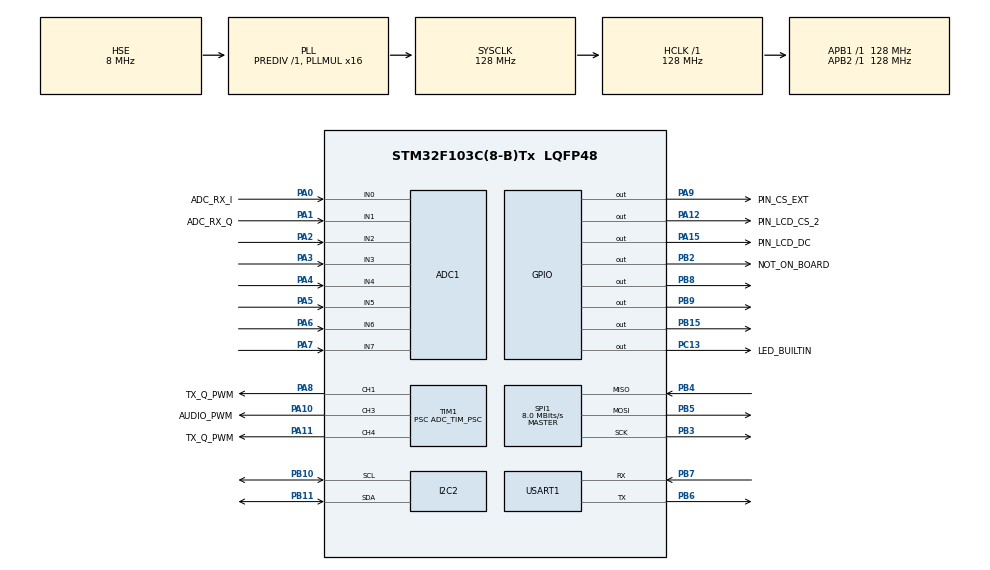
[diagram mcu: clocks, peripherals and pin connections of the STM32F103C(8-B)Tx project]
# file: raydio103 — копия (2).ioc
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ADC1.Channel-14\#ChannelRegularConversion=ADC_CHANNEL_1
ADC1.Channel-15\#ChannelInjectedConversion=ADC_CHANNEL_4
ADC1.Channel-16\#ChannelInjectedConversion=ADC_CHANNEL_5
ADC1.Channel-17\#ChannelRegularConversion=ADC_CHANNEL_2
ADC1.Channel-18\#ChannelRegularConversion=ADC_CHANNEL_3
ADC1.Channel-9\#ChannelRegularConversion=ADC_CHANNEL_0
ADC1.ContinuousConvMode=DISABLE
ADC1.DiscontinuousConvMode=DISABLE
ADC1.EnableInjectedConversion=ENABLE
ADC1.EnableRegularConversion=ENABLE
ADC1.ExternalTrigConv=ADC_EXTERNALTRIGCONV_T1_CC2
ADC1.InjNumberOfConversion=2
ADC1.InjectedConvMode=AutoInjected
ADC1.InjectedOffset-15\#ChannelInjectedConversion=0
ADC1.InjectedOffset-16\#ChannelInjectedConversion=0
ADC1.InjectedRank-15\#ChannelInjectedConversion=1
ADC1.InjectedRank-16\#ChannelInjectedConversion=2
ADC1.NbrOfConversion=4
ADC1.NbrOfConversionFlag=1
ADC1.Rank-14\#ChannelRegularConversion=2
ADC1.Rank-17\#ChannelRegularConversion=3
ADC1.Rank-18\#ChannelRegularConversion=4
ADC1.Rank-9\#ChannelRegularConversion=1
ADC1.SamplingTime-14\#ChannelRegularConversion=ADC_SAMPLETIME_71CYCLES_5
ADC1.SamplingTime-15\#ChannelInjectedConversion=ADC_SAMPLETIME_28CYCLES_5
ADC1.SamplingTime-16\#ChannelInjectedConversion=ADC_SAMPLETIME_28CYCLES_5
ADC1.SamplingTime-17\#ChannelRegularConversion=ADC_SAMPLETIME_71CYCLES_5
ADC1.SamplingTime-18\#ChannelRegularConversion=ADC_SAMPLETIME_71CYCLES_5
ADC1.SamplingTime-9\#ChannelRegularConversion=ADC_SAMPLETIME_71CYCLES_5
ADC1.master=1
Dma.ADC1.0.Direction=DMA_PERIPH_TO_MEMORY
Dma.ADC1.0.Instance=DMA1_Channel1
Dma.ADC1.0.MemDataAlignment=DMA_MDATAALIGN_HALFWORD
Dma.ADC1.0.MemInc=DMA_MINC_ENABLE
Dma.ADC1.0.Mode=DMA_CIRCULAR
Dma.ADC1.0.PeriphDataAlignment=DMA_PDATAALIGN_HALFWORD
Dma.ADC1.0.PeriphInc=DMA_PINC_DISABLE
Dma.ADC1.0.Priority=DMA_PRIORITY_VERY_HIGH
Dma.Request0=ADC1
Dma.Request1=TIM1_CH3
Dma.Request2=TIM1_CH4/TRIG/COM
Dma.Request3=TIM1_CH1
Dma.Request4=SPI1_TX
Dma.SPI1_TX.4.Direction=DMA_MEMORY_TO_PERIPH
Dma.SPI1_TX.4.Instance=DMA1_Channel3
Dma.SPI1_TX.4.MemDataAlignment=DMA_MDATAALIGN_BYTE
Dma.SPI1_TX.4.MemInc=DMA_MINC_ENABLE
Dma.SPI1_TX.4.Mode=DMA_NORMAL
Dma.SPI1_TX.4.PeriphDataAlignment=DMA_PDATAALIGN_BYTE
Dma.SPI1_TX.4.PeriphInc=DMA_PINC_DISABLE
Dma.SPI1_TX.4.Priority=DMA_PRIORITY_MEDIUM
Dma.TIM1_CH1.3.Direction=DMA_MEMORY_TO_PERIPH
Dma.TIM1_CH1.3.Instance=DMA1_Channel2
Dma.TIM1_CH1.3.MemDataAlignment=DMA_MDATAALIGN_HALFWORD
Dma.TIM1_CH1.3.MemInc=DMA_MINC_ENABLE
Dma.TIM1_CH1.3.Mode=DMA_NORMAL
Dma.TIM1_CH1.3.PeriphDataAlignment=DMA_PDATAALIGN_HALFWORD
Dma.TIM1_CH1.3.PeriphInc=DMA_PINC_DISABLE
Dma.TIM1_CH1.3.Priority=DMA_PRIORITY_LOW
Dma.TIM1_CH3.1.Direction=DMA_MEMORY_TO_PERIPH
Dma.TIM1_CH3.1.Instance=DMA1_Channel6
Dma.TIM1_CH3.1.MemDataAlignment=DMA_MDATAALIGN_HALFWORD
Dma.TIM1_CH3.1.MemInc=DMA_MINC_ENABLE
Dma.TIM1_CH3.1.Mode=DMA_CIRCULAR
Dma.TIM1_CH3.1.PeriphDataAlignment=DMA_PDATAALIGN_HALFWORD
Dma.TIM1_CH3.1.PeriphInc=DMA_PINC_DISABLE
Dma.TIM1_CH3.1.Priority=DMA_PRIORITY_HIGH
Dma.TIM1_CH4/TRIG/COM.2.Direction=DMA_MEMORY_TO_PERIPH
Dma.TIM1_CH4/TRIG/COM.2.Instance=DMA1_Channel4
Dma.TIM1_CH4/TRIG/COM.2.MemDataAlignment=DMA_MDATAALIGN_HALFWORD
Dma.TIM1_CH4/TRIG/COM.2.MemInc=DMA_MINC_ENABLE
Dma.TIM1_CH4/TRIG/COM.2.Mode=DMA_NORMAL
Dma.TIM1_CH4/TRIG/COM.2.PeriphDataAlignment=DMA_PDATAALIGN_HALFWORD
Dma.TIM1_CH4/TRIG/COM.2.PeriphInc=DMA_PINC_DISABLE
Dma.TIM1_CH4/TRIG/COM.2.Priority=DMA_PRIORITY_LOW
Mcu.Family=STM32F1
Mcu.Name=STM32F103C(8-B)Tx
Mcu.Package=LQFP48
Mcu.UserConstants=ADC_TIM_PSC,(2-1);ADC_TIM_PERIOD,(2048-1)
NVIC.DMA1_Channel1_IRQn=true\:0\:0\:false\:false\:true\:false\:true\:true
NVIC.DMA1_Channel2_IRQn=true\:0\:0\:false\:false\:true\:false\:true\:true
NVIC.DMA1_Channel3_IRQn=true\:0\:0\:false\:false\:true\:false\:true\:true
NVIC.DMA1_Channel4_IRQn=true\:0\:0\:false\:false\:true\:false\:true\:true
NVIC.DMA1_Channel6_IRQn=true\:0\:0\:false\:false\:true\:false\:true\:true
NVIC.PriorityGroup=NVIC_PRIORITYGROUP_4
NVIC.USART1_IRQn=true\:0\:0\:false\:false\:true\:true\:true\:true
PA0-WKUP.GPIO_Label=ADC_RX_I
PA0-WKUP.Signal=ADCx_IN0
PA1.GPIO_Label=ADC_RX_Q
PA1.Signal=ADCx_IN1
PA10.GPIO_Label=AUDIO_PWM
PA10.Signal=S_TIM1_CH3
PA11.GPIO_Label=TX_Q_PWM
PA11.Signal=S_TIM1_CH4
PA12.GPIO_Label=PIN_LCD_CS_2
PA12.GPIO_PuPd=GPIO_PULLUP
PA12.GPIO_Speed=GPIO_SPEED_FREQ_HIGH
PA12.PinState=GPIO_PIN_RESET
PA12.Signal=GPIO_Output
PA13.Mode=Serial_Wire
PA13.Signal=SYS_JTMS-SWDIO
PA14.Mode=Serial_Wire
PA14.Signal=SYS_JTCK-SWCLK
PA15.GPIO_Label=PIN_LCD_DC
PA15.GPIO_PuPd=GPIO_PULLDOWN
PA15.GPIO_Speed=GPIO_SPEED_FREQ_HIGH
PA15.Signal=GPIO_Output
PA2.Signal=ADCx_IN2
PA3.Signal=ADCx_IN3
PA4.Signal=ADCx_IN4
PA5.Signal=ADCx_IN5
PA6.Signal=ADCx_IN6
PA7.Signal=ADCx_IN7
PA8.GPIO_Label=TX_Q_PWM
PA8.Signal=S_TIM1_CH1
PA9.GPIO_Label=PIN_CS_EXT
PA9.Signal=GPIO_Output
PB10.Mode=I2C
PB10.Signal=I2C2_SCL
PB11.Mode=I2C
PB11.Signal=I2C2_SDA
PB15.Signal=GPIO_Output
PB2.GPIO_Label=NOT_ON_BOARD
PB2.Signal=GPIO_Output
PB3.Mode=Full_Duplex_Master
PB3.Signal=SPI1_SCK
PB4.Mode=Full_Duplex_Master
PB4.Signal=SPI1_MISO
PB5.Mode=Full_Duplex_Master
PB5.Signal=SPI1_MOSI
PB6.Mode=Asynchronous
PB6.Signal=USART1_TX
PB7.Mode=Asynchronous
PB7.Signal=USART1_RX
PB8.Signal=GPIO_Output
PB9.Signal=GPIO_Output
PC13-TAMPER-RTC.GPIO_Label=LED_BUILTIN
PC13-TAMPER-RTC.Signal=GPIO_Output
PC14-OSC32_IN.Mode=LSE-External-Oscillator
PC14-OSC32_IN.Signal=RCC_OSC32_IN
PC15-OSC32_OUT.Mode=LSE-External-Oscillator
PC15-OSC32_OUT.Signal=RCC_OSC32_OUT
PD0-OSC_IN.Mode=HSE-External-Oscillator
PD0-OSC_IN.Signal=RCC_OSC_IN
PD1-OSC_OUT.Mode=HSE-External-Oscillator
PD1-OSC_OUT.Signal=RCC_OSC_OUT
ProjectManager.HeapSize=0x400
ProjectManager.StackSize=0x200
ProjectManager.TargetToolchain=STM32CubeIDE
RCC.ADCPresc=RCC_ADCPCLK2_DIV4
RCC.AHBFreq_Value=128000000
RCC.APB1Freq_Value=128000000
RCC.APB1TimFreq_Value=128000000
RCC.APB2Freq_Value=128000000
RCC.APB2TimFreq_Value=128000000
RCC.HCLKFreq_Value=128000000
RCC.PLLMUL=RCC_PLL_MUL16
RCC.PLLSourceVirtual=RCC_PLLSOURCE_HSE
RCC.SYSCLKFreq_VALUE=128000000
RCC.SYSCLKSource=RCC_SYSCLKSOURCE_PLLCLK
RCC.USBFreq_Value=85333333.33333333
RCC.USBPrescaler=RCC_USBCLKSOURCE_PLL_DIV1_5
RTC.Format=RTC_FORMAT_BIN
SH.ADCx_IN0.0=ADC1_IN0,IN0
SH.ADCx_IN1.0=ADC1_IN1,IN1
SH.ADCx_IN2.0=ADC1_IN2,IN2
SH.ADCx_IN3.0=ADC1_IN3,IN3
SH.ADCx_IN4.0=ADC1_IN4,IN4
SH.ADCx_IN5.0=ADC1_IN5,IN5
SH.ADCx_IN6.0=ADC1_IN6,IN6
SH.ADCx_IN7.0=ADC1_IN7,IN7
SH.S_TIM1_CH1.0=TIM1_CH1,PWM Generation1 CH1
SH.S_TIM1_CH3.0=TIM1_CH3,PWM Generation3 CH3
SH.S_TIM1_CH4.0=TIM1_CH4,PWM Generation4 CH4
SPI1.BaudRatePrescaler=SPI_BAUDRATEPRESCALER_16
SPI1.CLKPhase=SPI_PHASE_1EDGE
SPI1.CLKPolarity=SPI_POLARITY_LOW
SPI1.CalculateBaudRate=8.0 MBits/s
SPI1.Direction=SPI_DIRECTION_2LINES
SPI1.Mode=SPI_MODE_MASTER
SPI1.VirtualType=VM_MASTER
TIM1.AutoReloadPreload=TIM_AUTORELOAD_PRELOAD_ENABLE
TIM1.Channel-PWM\ Generation1\ CH1=TIM_CHANNEL_1
TIM1.Channel-PWM\ Generation2\ No\ Output=TIM_CHANNEL_2
TIM1.Channel-PWM\ Generation3\ CH3=TIM_CHANNEL_3
TIM1.Channel-PWM\ Generation4\ CH4=TIM_CHANNEL_4
TIM1.ClockDivision=TIM_CLOCKDIVISION_DIV1
TIM1.Period=ADC_TIM_PERIOD
TIM1.Prescaler=ADC_TIM_PSC
TIM1.Pulse-PWM\ Generation2\ No\ Output=1
TIM1.Pulse-PWM\ Generation3\ CH3=0
TIM1.TIM_MasterOutputTrigger=TIM_TRGO_ENABLE
TIM1.TIM_MasterSlaveMode=TIM_MASTERSLAVEMODE_DISABLE
TIM2.Channel-PWM\ Generation2\ No\ Output=TIM_CHANNEL_2
TIM2.Period=ADC_TIM_PERIOD
TIM2.Prescaler=ADC_TIM_PSC
TIM2.Pulse-PWM\ Generation2\ No\ Output=1
TIM2.TIM_MasterOutputTrigger=TIM_TRGO_ENABLE
TIM2.TIM_MasterSlaveMode=TIM_MASTERSLAVEMODE_ENABLE
USART1.VirtualMode=VM_ASYNC
VP_CRC_VS_CRC.Mode=CRC_Activate
VP_RTC_VS_RTC_Activate.Mode=RTC_Enabled
VP_TIM1_VS_ClockSourceINT.Mode=Internal
VP_TIM1_VS_no_output2.Mode=PWM Generation2 No Output
VP_TIM2_VS_ClockSourceINT.Mode=Internal
VP_TIM2_VS_ClockSourceITR.Mode=TriggerSource_ITR0
VP_TIM2_VS_ControllerModeTrigger.Mode=Trigger Mode
VP_TIM2_VS_no_output2.Mode=PWM Generation2 No Output
board=custom

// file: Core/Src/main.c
/* USER CODE BEGIN Header */
/**
  ******************************************************************************
  * @file           : main.c
  * @brief          : Main program body
  ******************************************************************************
  * @attention
  *
  * Copyright (c) 2022 STMicroelectronics.
  * All rights reserved.
  *
  * This software is licensed under terms that can be found in the LICENSE file
  * in the root directory of this software component.
  * If no LICENSE file comes with this software, it is provided AS-IS.
  *
  ******************************************************************************
  */
/* USER CODE END Header */
#include "main.h"

 ADC_HandleTypeDef hadc1;
DMA_HandleTypeDef hdma_adc1;

CRC_HandleTypeDef hcrc;

I2C_HandleTypeDef hi2c2;

RTC_HandleTypeDef hrtc;

SPI_HandleTypeDef hspi1;
DMA_HandleTypeDef hdma_spi1_tx;

TIM_HandleTypeDef htim1;
TIM_HandleTypeDef htim2;
DMA_HandleTypeDef hdma_tim1_ch3;
DMA_HandleTypeDef hdma_tim1_ch4_trig_com;
DMA_HandleTypeDef hdma_tim1_ch1;

UART_HandleTypeDef huart1;

void SystemClock_Config(void);
static void MX_GPIO_Init(void);
static void MX_DMA_Init(void);
static void MX_ADC1_Init(void);
static void MX_TIM1_Init(void);
static void MX_SPI1_Init(void);
static void MX_USART1_UART_Init(void);
static void MX_TIM2_Init(void);
static void MX_I2C2_Init(void);
static void MX_RTC_Init(void);
static void MX_CRC_Init(void);

int main(void)
{

  /* MCU Configuration--------------------------------------------------------*/

  /* Reset of all peripherals, Initializes the Flash interface and the Systick. */
  HAL_Init();

  /* Configure the system clock */
  SystemClock_Config();

  /* Initialize all configured peripherals */
  MX_GPIO_Init();
  MX_DMA_Init();
  MX_ADC1_Init();
  MX_TIM1_Init();
  MX_SPI1_Init();
  MX_USART1_UART_Init();
  MX_TIM2_Init();
  MX_I2C2_Init();
  MX_RTC_Init();
  MX_CRC_Init();

  /* Infinite loop */
  /* USER CODE BEGIN WHILE */

  schedRun();

  while (1)
  {
    /* USER CODE END WHILE */

  }
}

void SystemClock_Config(void)
{
  RCC_OscInitTypeDef RCC_OscInitStruct = {0};
  RCC_ClkInitTypeDef RCC_ClkInitStruct = {0};
  RCC_PeriphCLKInitTypeDef PeriphClkInit = {0};

  /** Initializes the RCC Oscillators according to the specified parameters
  * in the RCC_OscInitTypeDef structure.
  */
  RCC_OscInitStruct.OscillatorType = RCC_OSCILLATORTYPE_LSI|RCC_OSCILLATORTYPE_HSE;
  RCC_OscInitStruct.HSEState = RCC_HSE_ON;
  RCC_OscInitStruct.HSEPredivValue = RCC_HSE_PREDIV_DIV1;
  RCC_OscInitStruct.HSIState = RCC_HSI_ON;
  RCC_OscInitStruct.LSIState = RCC_LSI_ON;
  RCC_OscInitStruct.PLL.PLLState = RCC_PLL_ON;
  RCC_OscInitStruct.PLL.PLLSource = RCC_PLLSOURCE_HSE;
  RCC_OscInitStruct.PLL.PLLMUL = RCC_PLL_MUL16;
  if (HAL_RCC_OscConfig(&RCC_OscInitStruct) != HAL_OK)
  {
    Error_Handler();
  }

  /** Initializes the CPU, AHB and APB buses clocks
  */
  RCC_ClkInitStruct.ClockType = RCC_CLOCKTYPE_HCLK|RCC_CLOCKTYPE_SYSCLK
                              |RCC_CLOCKTYPE_PCLK1|RCC_CLOCKTYPE_PCLK2;
  RCC_ClkInitStruct.SYSCLKSource = RCC_SYSCLKSOURCE_PLLCLK;
  RCC_ClkInitStruct.AHBCLKDivider = RCC_SYSCLK_DIV1;
  RCC_ClkInitStruct.APB1CLKDivider = RCC_HCLK_DIV1;
  RCC_ClkInitStruct.APB2CLKDivider = RCC_HCLK_DIV1;

  if (HAL_RCC_ClockConfig(&RCC_ClkInitStruct, FLASH_LATENCY_2) != HAL_OK)
  {
    Error_Handler();
  }
  PeriphClkInit.PeriphClockSelection = RCC_PERIPHCLK_RTC|RCC_PERIPHCLK_ADC;
  PeriphClkInit.RTCClockSelection = RCC_RTCCLKSOURCE_LSI;
  PeriphClkInit.AdcClockSelection = RCC_ADCPCLK2_DIV4;
  if (HAL_RCCEx_PeriphCLKConfig(&PeriphClkInit) != HAL_OK)
  {
    Error_Handler();
  }
}

static void MX_ADC1_Init(void)
{

  ADC_ChannelConfTypeDef sConfig = {0};
  ADC_InjectionConfTypeDef sConfigInjected = {0};

  /** Common config
  */
  hadc1.Instance = ADC1;
  hadc1.Init.ScanConvMode = ADC_SCAN_ENABLE;
  hadc1.Init.ContinuousConvMode = DISABLE;
  hadc1.Init.DiscontinuousConvMode = DISABLE;
  hadc1.Init.ExternalTrigConv = ADC_EXTERNALTRIGCONV_T1_CC2;
  hadc1.Init.DataAlign = ADC_DATAALIGN_RIGHT;
  hadc1.Init.NbrOfConversion = 4;
  if (HAL_ADC_Init(&hadc1) != HAL_OK)
  {
    Error_Handler();
  }

  /** Configure Regular Channel
  */
  sConfig.Channel = ADC_CHANNEL_0;
  sConfig.Rank = ADC_REGULAR_RANK_1;
  sConfig.SamplingTime = ADC_SAMPLETIME_71CYCLES_5;
  if (HAL_ADC_ConfigChannel(&hadc1, &sConfig) != HAL_OK)
  {
    Error_Handler();
  }

  /** Configure Regular Channel
  */
  sConfig.Channel = ADC_CHANNEL_1;
  sConfig.Rank = ADC_REGULAR_RANK_2;
  if (HAL_ADC_ConfigChannel(&hadc1, &sConfig) != HAL_OK)
  {
    Error_Handler();
  }

  /** Configure Regular Channel
  */
  sConfig.Channel = ADC_CHANNEL_2;
  sConfig.Rank = ADC_REGULAR_RANK_3;
  if (HAL_ADC_ConfigChannel(&hadc1, &sConfig) != HAL_OK)
  {
    Error_Handler();
  }

  /** Configure Regular Channel
  */
  sConfig.Channel = ADC_CHANNEL_3;
  sConfig.Rank = ADC_REGULAR_RANK_4;
  if (HAL_ADC_ConfigChannel(&hadc1, &sConfig) != HAL_OK)
  {
    Error_Handler();
  }

  /** Configure Injected Channel
  */
  sConfigInjected.InjectedChannel = ADC_CHANNEL_4;
  sConfigInjected.InjectedRank = ADC_INJECTED_RANK_1;
  sConfigInjected.InjectedNbrOfConversion = 2;
  sConfigInjected.InjectedSamplingTime = ADC_SAMPLETIME_28CYCLES_5;
  sConfigInjected.ExternalTrigInjecConv = ADC_INJECTED_SOFTWARE_START;
  sConfigInjected.AutoInjectedConv = ENABLE;
  sConfigInjected.InjectedDiscontinuousConvMode = DISABLE;
  sConfigInjected.InjectedOffset = 0;
  if (HAL_ADCEx_InjectedConfigChannel(&hadc1, &sConfigInjected) != HAL_OK)
  {
    Error_Handler();
  }

  /** Configure Injected Channel
  */
  sConfigInjected.InjectedChannel = ADC_CHANNEL_5;
  sConfigInjected.InjectedRank = ADC_INJECTED_RANK_2;
  if (HAL_ADCEx_InjectedConfigChannel(&hadc1, &sConfigInjected) != HAL_OK)
  {
    Error_Handler();
  }

}

static void MX_CRC_Init(void)
{

  hcrc.Instance = CRC;
  if (HAL_CRC_Init(&hcrc) != HAL_OK)
  {
    Error_Handler();
  }

}

static void MX_I2C2_Init(void)
{

  hi2c2.Instance = I2C2;
  hi2c2.Init.ClockSpeed = 100000;
  hi2c2.Init.DutyCycle = I2C_DUTYCYCLE_2;
  hi2c2.Init.OwnAddress1 = 0;
  hi2c2.Init.AddressingMode = I2C_ADDRESSINGMODE_7BIT;
  hi2c2.Init.DualAddressMode = I2C_DUALADDRESS_DISABLE;
  hi2c2.Init.OwnAddress2 = 0;
  hi2c2.Init.GeneralCallMode = I2C_GENERALCALL_DISABLE;
  hi2c2.Init.NoStretchMode = I2C_NOSTRETCH_DISABLE;
  if (HAL_I2C_Init(&hi2c2) != HAL_OK)
  {
    Error_Handler();
  }

}

static void MX_RTC_Init(void)
{

  /** Initialize RTC Only
  */
  hrtc.Instance = RTC;
  hrtc.Init.AsynchPrediv = RTC_AUTO_1_SECOND;
  hrtc.Init.OutPut = RTC_OUTPUTSOURCE_ALARM;
  if (HAL_RTC_Init(&hrtc) != HAL_OK)
  {
    Error_Handler();
  }

}

static void MX_SPI1_Init(void)
{

  /* SPI1 parameter configuration*/
  hspi1.Instance = SPI1;
  hspi1.Init.Mode = SPI_MODE_MASTER;
  hspi1.Init.Direction = SPI_DIRECTION_2LINES;
  hspi1.Init.DataSize = SPI_DATASIZE_8BIT;
  hspi1.Init.CLKPolarity = SPI_POLARITY_LOW;
  hspi1.Init.CLKPhase = SPI_PHASE_1EDGE;
  hspi1.Init.NSS = SPI_NSS_SOFT;
  hspi1.Init.BaudRatePrescaler = SPI_BAUDRATEPRESCALER_16;
  hspi1.Init.FirstBit = SPI_FIRSTBIT_MSB;
  hspi1.Init.TIMode = SPI_TIMODE_DISABLE;
  hspi1.Init.CRCCalculation = SPI_CRCCALCULATION_DISABLE;
  hspi1.Init.CRCPolynomial = 10;
  if (HAL_SPI_Init(&hspi1) != HAL_OK)
  {
    Error_Handler();
  }

}

static void MX_TIM1_Init(void)
{

  TIM_ClockConfigTypeDef sClockSourceConfig = {0};
  TIM_MasterConfigTypeDef sMasterConfig = {0};
  TIM_OC_InitTypeDef sConfigOC = {0};
  TIM_BreakDeadTimeConfigTypeDef sBreakDeadTimeConfig = {0};

  htim1.Instance = TIM1;
  htim1.Init.Prescaler = ADC_TIM_PSC;
  htim1.Init.CounterMode = TIM_COUNTERMODE_UP;
  htim1.Init.Period = ADC_TIM_PERIOD;
  htim1.Init.ClockDivision = TIM_CLOCKDIVISION_DIV1;
  htim1.Init.RepetitionCounter = 0;
  htim1.Init.AutoReloadPreload = TIM_AUTORELOAD_PRELOAD_ENABLE;
  if (HAL_TIM_Base_Init(&htim1) != HAL_OK)
  {
    Error_Handler();
  }
  sClockSourceConfig.ClockSource = TIM_CLOCKSOURCE_INTERNAL;
  if (HAL_TIM_ConfigClockSource(&htim1, &sClockSourceConfig) != HAL_OK)
  {
    Error_Handler();
  }
  if (HAL_TIM_PWM_Init(&htim1) != HAL_OK)
  {
    Error_Handler();
  }
  sMasterConfig.MasterOutputTrigger = TIM_TRGO_ENABLE;
  sMasterConfig.MasterSlaveMode = TIM_MASTERSLAVEMODE_DISABLE;
  if (HAL_TIMEx_MasterConfigSynchronization(&htim1, &sMasterConfig) != HAL_OK)
  {
    Error_Handler();
  }
  sConfigOC.OCMode = TIM_OCMODE_PWM1;
  sConfigOC.Pulse = 0;
  sConfigOC.OCPolarity = TIM_OCPOLARITY_HIGH;
  sConfigOC.OCNPolarity = TIM_OCNPOLARITY_HIGH;
  sConfigOC.OCFastMode = TIM_OCFAST_DISABLE;
  sConfigOC.OCIdleState = TIM_OCIDLESTATE_RESET;
  sConfigOC.OCNIdleState = TIM_OCNIDLESTATE_RESET;
  if (HAL_TIM_PWM_ConfigChannel(&htim1, &sConfigOC, TIM_CHANNEL_1) != HAL_OK)
  {
    Error_Handler();
  }
  sConfigOC.Pulse = 1;
  if (HAL_TIM_PWM_ConfigChannel(&htim1, &sConfigOC, TIM_CHANNEL_2) != HAL_OK)
  {
    Error_Handler();
  }
  sConfigOC.Pulse = 0;
  if (HAL_TIM_PWM_ConfigChannel(&htim1, &sConfigOC, TIM_CHANNEL_3) != HAL_OK)
  {
    Error_Handler();
  }
  if (HAL_TIM_PWM_ConfigChannel(&htim1, &sConfigOC, TIM_CHANNEL_4) != HAL_OK)
  {
    Error_Handler();
  }
  sBreakDeadTimeConfig.OffStateRunMode = TIM_OSSR_DISABLE;
  sBreakDeadTimeConfig.OffStateIDLEMode = TIM_OSSI_DISABLE;
  sBreakDeadTimeConfig.LockLevel = TIM_LOCKLEVEL_OFF;
  sBreakDeadTimeConfig.DeadTime = 0;
  sBreakDeadTimeConfig.BreakState = TIM_BREAK_DISABLE;
  sBreakDeadTimeConfig.BreakPolarity = TIM_BREAKPOLARITY_HIGH;
  sBreakDeadTimeConfig.AutomaticOutput = TIM_AUTOMATICOUTPUT_DISABLE;
  if (HAL_TIMEx_ConfigBreakDeadTime(&htim1, &sBreakDeadTimeConfig) != HAL_OK)
  {
    Error_Handler();
  }
  HAL_TIM_MspPostInit(&htim1);

}

static void MX_TIM2_Init(void)
{

  TIM_ClockConfigTypeDef sClockSourceConfig = {0};
  TIM_SlaveConfigTypeDef sSlaveConfig = {0};
  TIM_MasterConfigTypeDef sMasterConfig = {0};
  TIM_OC_InitTypeDef sConfigOC = {0};

  htim2.Instance = TIM2;
  htim2.Init.Prescaler = ADC_TIM_PSC;
  htim2.Init.CounterMode = TIM_COUNTERMODE_UP;
  htim2.Init.Period = ADC_TIM_PERIOD;
  htim2.Init.ClockDivision = TIM_CLOCKDIVISION_DIV1;
  htim2.Init.AutoReloadPreload = TIM_AUTORELOAD_PRELOAD_DISABLE;
  if (HAL_TIM_Base_Init(&htim2) != HAL_OK)
  {
    Error_Handler();
  }
  sClockSourceConfig.ClockSource = TIM_CLOCKSOURCE_INTERNAL;
  if (HAL_TIM_ConfigClockSource(&htim2, &sClockSourceConfig) != HAL_OK)
  {
    Error_Handler();
  }
  if (HAL_TIM_PWM_Init(&htim2) != HAL_OK)
  {
    Error_Handler();
  }
  sSlaveConfig.SlaveMode = TIM_SLAVEMODE_TRIGGER;
  sSlaveConfig.InputTrigger = TIM_TS_ITR0;
  if (HAL_TIM_SlaveConfigSynchro(&htim2, &sSlaveConfig) != HAL_OK)
  {
    Error_Handler();
  }
  sMasterConfig.MasterOutputTrigger = TIM_TRGO_ENABLE;
  sMasterConfig.MasterSlaveMode = TIM_MASTERSLAVEMODE_ENABLE;
  if (HAL_TIMEx_MasterConfigSynchronization(&htim2, &sMasterConfig) != HAL_OK)
  {
    Error_Handler();
  }
  sConfigOC.OCMode = TIM_OCMODE_PWM1;
  sConfigOC.Pulse = 1;
  sConfigOC.OCPolarity = TIM_OCPOLARITY_HIGH;
  sConfigOC.OCFastMode = TIM_OCFAST_DISABLE;
  if (HAL_TIM_PWM_ConfigChannel(&htim2, &sConfigOC, TIM_CHANNEL_2) != HAL_OK)
  {
    Error_Handler();
  }

}

static void MX_USART1_UART_Init(void)
{

  huart1.Instance = USART1;
  huart1.Init.BaudRate = 115200;
  huart1.Init.WordLength = UART_WORDLENGTH_8B;
  huart1.Init.StopBits = UART_STOPBITS_1;
  huart1.Init.Parity = UART_PARITY_NONE;
  huart1.Init.Mode = UART_MODE_TX_RX;
  huart1.Init.HwFlowCtl = UART_HWCONTROL_NONE;
  huart1.Init.OverSampling = UART_OVERSAMPLING_16;
  if (HAL_UART_Init(&huart1) != HAL_OK)
  {
    Error_Handler();
  }

}

static void MX_DMA_Init(void)
{

  /* DMA controller clock enable */
  __HAL_RCC_DMA1_CLK_ENABLE();

  /* DMA interrupt init */
  /* DMA1_Channel1_IRQn interrupt configuration */
  HAL_NVIC_SetPriority(DMA1_Channel1_IRQn, 0, 0);
  HAL_NVIC_EnableIRQ(DMA1_Channel1_IRQn);
  /* DMA1_Channel2_IRQn interrupt configuration */
  HAL_NVIC_SetPriority(DMA1_Channel2_IRQn, 0, 0);
  HAL_NVIC_EnableIRQ(DMA1_Channel2_IRQn);
  /* DMA1_Channel3_IRQn interrupt configuration */
  HAL_NVIC_SetPriority(DMA1_Channel3_IRQn, 0, 0);
  HAL_NVIC_EnableIRQ(DMA1_Channel3_IRQn);
  /* DMA1_Channel4_IRQn interrupt configuration */
  HAL_NVIC_SetPriority(DMA1_Channel4_IRQn, 0, 0);
  HAL_NVIC_EnableIRQ(DMA1_Channel4_IRQn);
  /* DMA1_Channel6_IRQn interrupt configuration */
  HAL_NVIC_SetPriority(DMA1_Channel6_IRQn, 0, 0);
  HAL_NVIC_EnableIRQ(DMA1_Channel6_IRQn);

}

static void MX_GPIO_Init(void)
{
  GPIO_InitTypeDef GPIO_InitStruct = {0};

  /* GPIO Ports Clock Enable */
  __HAL_RCC_GPIOC_CLK_ENABLE();
  __HAL_RCC_GPIOD_CLK_ENABLE();
  __HAL_RCC_GPIOA_CLK_ENABLE();
  __HAL_RCC_GPIOB_CLK_ENABLE();

  /*Configure GPIO pin Output Level */
  HAL_GPIO_WritePin(LED_BUILTIN_GPIO_Port, LED_BUILTIN_Pin, GPIO_PIN_RESET);

  /*Configure GPIO pin Output Level */
  HAL_GPIO_WritePin(GPIOB, GPIO_PIN_15|GPIO_PIN_8|GPIO_PIN_9, GPIO_PIN_RESET);

  /*Configure GPIO pin Output Level */
  HAL_GPIO_WritePin(GPIOA, PIN_CS_EXT_Pin|PIN_LCD_CS_2_Pin|PIN_LCD_DC_Pin, GPIO_PIN_RESET);

  /*Configure GPIO pin : LED_BUILTIN_Pin */
  GPIO_InitStruct.Pin = LED_BUILTIN_Pin;
  GPIO_InitStruct.Mode = GPIO_MODE_OUTPUT_PP;
  GPIO_InitStruct.Pull = GPIO_NOPULL;
  GPIO_InitStruct.Speed = GPIO_SPEED_FREQ_LOW;
  HAL_GPIO_Init(LED_BUILTIN_GPIO_Port, &GPIO_InitStruct);

  /*Configure GPIO pins : PB15 PB8 PB9 */
  GPIO_InitStruct.Pin = GPIO_PIN_15|GPIO_PIN_8|GPIO_PIN_9;
  GPIO_InitStruct.Mode = GPIO_MODE_OUTPUT_PP;
  GPIO_InitStruct.Pull = GPIO_NOPULL;
  GPIO_InitStruct.Speed = GPIO_SPEED_FREQ_LOW;
  HAL_GPIO_Init(GPIOB, &GPIO_InitStruct);

  /*Configure GPIO pin : PIN_CS_EXT_Pin */
  GPIO_InitStruct.Pin = PIN_CS_EXT_Pin;
  GPIO_InitStruct.Mode = GPIO_MODE_OUTPUT_PP;
  GPIO_InitStruct.Pull = GPIO_NOPULL;
  GPIO_InitStruct.Speed = GPIO_SPEED_FREQ_LOW;
  HAL_GPIO_Init(PIN_CS_EXT_GPIO_Port, &GPIO_InitStruct);

  /*Configure GPIO pin : PIN_LCD_CS_2_Pin */
  GPIO_InitStruct.Pin = PIN_LCD_CS_2_Pin;
  GPIO_InitStruct.Mode = GPIO_MODE_OUTPUT_PP;
  GPIO_InitStruct.Pull = GPIO_PULLUP;
  GPIO_InitStruct.Speed = GPIO_SPEED_FREQ_HIGH;
  HAL_GPIO_Init(PIN_LCD_CS_2_GPIO_Port, &GPIO_InitStruct);

  /*Configure GPIO pin : PIN_LCD_DC_Pin */
  GPIO_InitStruct.Pin = PIN_LCD_DC_Pin;
  GPIO_InitStruct.Mode = GPIO_MODE_OUTPUT_PP;
  GPIO_InitStruct.Pull = GPIO_PULLDOWN;
  GPIO_InitStruct.Speed = GPIO_SPEED_FREQ_HIGH;
  HAL_GPIO_Init(PIN_LCD_DC_GPIO_Port, &GPIO_InitStruct);

}

void Error_Handler(void)
{
  __disable_irq();
  while (1)
  {
  }
}
